AUTOSAR XML (schema 2.1.2)
standard types defined: Boolean
package /Komfortsystem
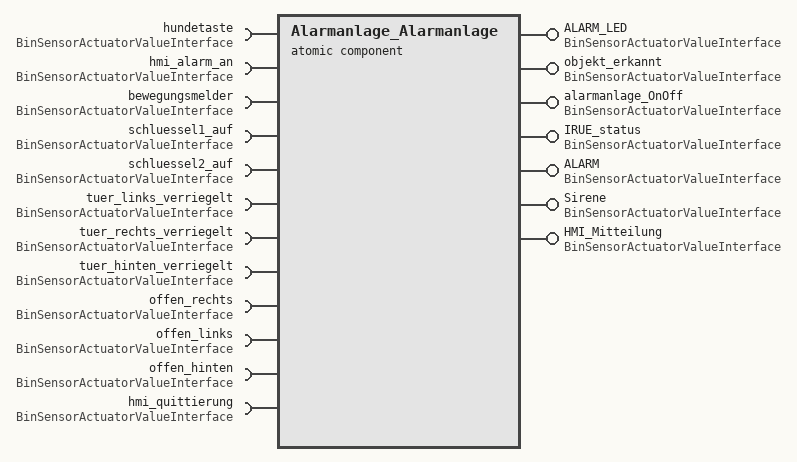
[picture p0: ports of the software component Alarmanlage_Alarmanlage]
  atomic software component type Alarmanlage_Alarmanlage  # @isComplex true
    11 x require port, all with required-interface=BinSensorActuatorValueInterface:
      hundetaste
      hmi_alarm_an
      bewegungsmelder
      schluessel1_auf
      schluessel2_auf
      tuer_links_verriegelt
      tuer_rechts_verriegelt
      tuer_hinten_verriegelt
      offen_rechts
      offen_links
      offen_hinten
    7 x provide port, all with provided-interface=BinSensorActuatorValueInterface:
      ALARM_LED
      objekt_erkannt
      alarmanlage_OnOff
      IRUE_status
      ALARM
      Sirene
      HMI_Mitteilung
    require port hmi_quittierung: required-interface=BinSensorActuatorValueInterface
  atomic software component type Alarmanlage_Bewegungsmelder  # __Sensor_Bewegungsmelder
    provide port status: provided-interface=BinSensorActuatorValueInterface
  atomic software component type Alarmanlage_Hundetaste  # __Sensor_Taster
    provide port taster_value: provided-interface=BinSensorActuatorValueInterface
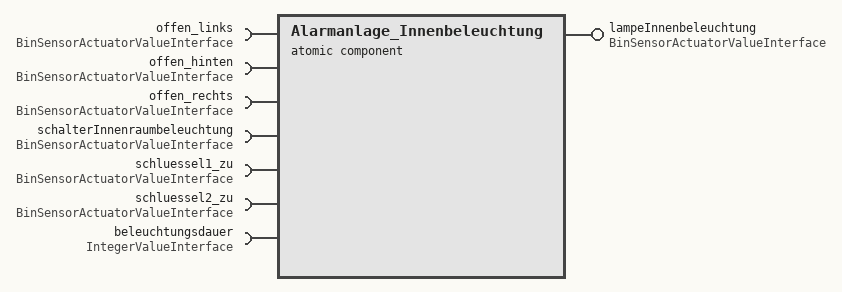
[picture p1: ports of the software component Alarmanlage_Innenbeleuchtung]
  atomic software component type Alarmanlage_Innenbeleuchtung  # @isComplex true
    7 x require port:
      offen_links: required-interface=BinSensorActuatorValueInterface
      offen_hinten: required-interface=BinSensorActuatorValueInterface
      offen_rechts: required-interface=BinSensorActuatorValueInterface
      schalterInnenraumbeleuchtung: required-interface=BinSensorActuatorValueInterface
      schluessel1_zu: required-interface=BinSensorActuatorValueInterface
      schluessel2_zu: required-interface=BinSensorActuatorValueInterface
      beleuchtungsdauer: required-interface=IntegerValueInterface
    provide port lampeInnenbeleuchtung: provided-interface=BinSensorActuatorValueInterface
  atomic software component type Alarmanlage_InnenbeleuchtungLampe  # __Actuator_LampeInnenbeleuchtung
    require port newStatus: required-interface=BinSensorActuatorValueInterface
  atomic software component type Alarmanlage_InnenraumBeleuchtungTaster  # __Sensor_Taster
    provide port taster_value: provided-interface=BinSensorActuatorValueInterface
  atomic software component type Alarmanlage_LED  # __Actuator_LED
    require port newStatus: required-interface=BinSensorActuatorValueInterface
  atomic software component type Alarmanlage_Sirene  # __Actuator_Sirene
    require port status: required-interface=BinSensorActuatorValueInterface
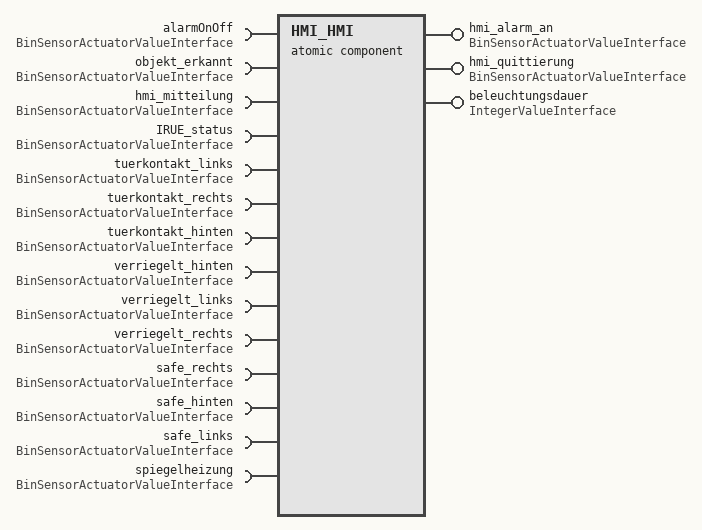
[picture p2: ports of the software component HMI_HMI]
  atomic software component type HMI_HMI  # @isComplex true
    13 x require port, all with required-interface=BinSensorActuatorValueInterface:
      alarmOnOff
      objekt_erkannt
      hmi_mitteilung
      IRUE_status
      tuerkontakt_links
      tuerkontakt_rechts
      tuerkontakt_hinten
      verriegelt_hinten
      verriegelt_links
      verriegelt_rechts
      safe_rechts
      safe_hinten
      safe_links
    provide port hmi_alarm_an: provided-interface=BinSensorActuatorValueInterface
    provide port hmi_quittierung: provided-interface=BinSensorActuatorValueInterface
    provide port beleuchtungsdauer: provided-interface=IntegerValueInterface
    require port spiegelheizung: required-interface=BinSensorActuatorValueInterface
  atomic software component type SensorAussentemperatur
    provide port unterEinGrad: provided-interface=BinSensorActuatorValueInterface
  atomic software component type SensorGeschwindigkeit
    provide port geschwindigkeit: provided-interface=IntegerValueInterface
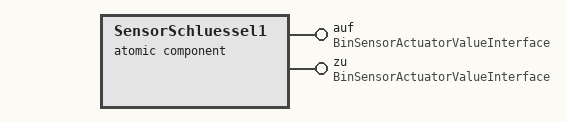
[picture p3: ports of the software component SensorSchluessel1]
  atomic software component type SensorSchluessel1
    provide port auf: provided-interface=BinSensorActuatorValueInterface
    provide port zu: provided-interface=BinSensorActuatorValueInterface
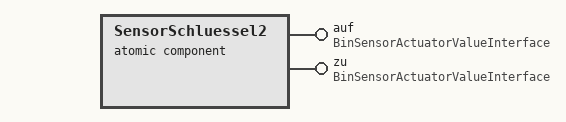
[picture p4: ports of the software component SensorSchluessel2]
  atomic software component type SensorSchluessel2
    provide port auf: provided-interface=BinSensorActuatorValueInterface
    provide port zu: provided-interface=BinSensorActuatorValueInterface
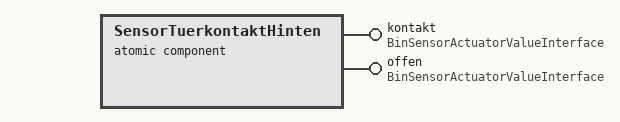
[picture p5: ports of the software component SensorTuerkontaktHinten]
  atomic software component type SensorTuerkontaktHinten
    provide port kontakt: provided-interface=BinSensorActuatorValueInterface
    provide port offen: provided-interface=BinSensorActuatorValueInterface
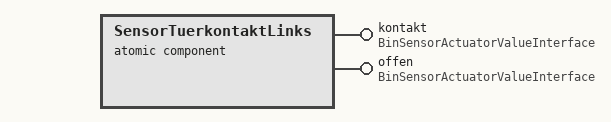
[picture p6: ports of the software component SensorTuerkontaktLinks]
  atomic software component type SensorTuerkontaktLinks
    provide port kontakt: provided-interface=BinSensorActuatorValueInterface
    provide port offen: provided-interface=BinSensorActuatorValueInterface
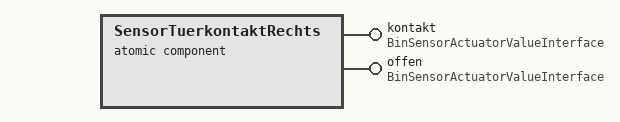
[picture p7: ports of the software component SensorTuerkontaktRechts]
  atomic software component type SensorTuerkontaktRechts
    provide port kontakt: provided-interface=BinSensorActuatorValueInterface
    provide port offen: provided-interface=BinSensorActuatorValueInterface
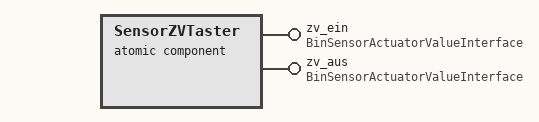
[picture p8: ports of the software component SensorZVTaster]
  atomic software component type SensorZVTaster
    provide port zv_ein: provided-interface=BinSensorActuatorValueInterface
    provide port zv_aus: provided-interface=BinSensorActuatorValueInterface
  atomic software component type TasterBlinker
    provide port taster_value: provided-interface=BinSensorActuatorValueInterface
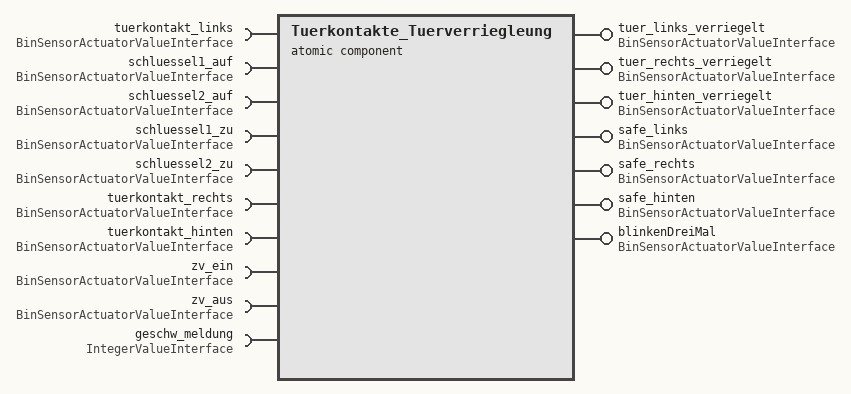
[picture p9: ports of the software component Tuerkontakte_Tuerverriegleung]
  atomic software component type Tuerkontakte_Tuerverriegleung  # @isComplex true
    10 x require port:
      tuerkontakt_links: required-interface=BinSensorActuatorValueInterface
      schluessel1_auf: required-interface=BinSensorActuatorValueInterface
      schluessel2_auf: required-interface=BinSensorActuatorValueInterface
      schluessel1_zu: required-interface=BinSensorActuatorValueInterface
      schluessel2_zu: required-interface=BinSensorActuatorValueInterface
      tuerkontakt_rechts: required-interface=BinSensorActuatorValueInterface
      tuerkontakt_hinten: required-interface=BinSensorActuatorValueInterface
      zv_ein: required-interface=BinSensorActuatorValueInterface
      zv_aus: required-interface=BinSensorActuatorValueInterface
      geschw_meldung: required-interface=IntegerValueInterface
    7 x provide port, all with provided-interface=BinSensorActuatorValueInterface:
      tuer_links_verriegelt
      tuer_rechts_verriegelt
      tuer_hinten_verriegelt
      safe_links
      safe_rechts
      safe_hinten
      blinkenDreiMal
  atomic software component type Tuersystem_Blinker
    require port blinker_status: required-interface=BinSensorActuatorValueInterface
  atomic software component type Tuersystem_Blinkerfunktionalitaet  # @isComplex true
    require port Blinker_CAN: required-interface=BinSensorActuatorValueInterface
    require port BlinkenDreiMal: required-interface=BinSensorActuatorValueInterface
    require port ALARM: required-interface=BinSensorActuatorValueInterface
    provide port blinker_status: provided-interface=BinSensorActuatorValueInterface
  atomic software component type Tuersystem_Fensterheber_BCD_A  # Actuator_LED
    require port newStatus: required-interface=BinSensorActuatorValueInterface
  atomic software component type Tuersystem_Fensterheber_BCD_B  # Actuator_LED
    require port newStatus: required-interface=BinSensorActuatorValueInterface
  atomic software component type Tuersystem_Fensterheber_BCD_C  # Actuator_LED
    require port newStatus: required-interface=BinSensorActuatorValueInterface
  atomic software component type Tuersystem_Fensterheber_BCD_D  # Actuator_LED
    require port newStatus: required-interface=BinSensorActuatorValueInterface
  atomic software component type Tuersystem_Fensterheber_Fensterbewegen  # @isComplex true
    4 x require port, all with required-interface=BinSensorActuatorValueInterface:
      fenster_hoch
      fenster_runter
      zv_ein
      init_abgeschlossen
    provide port fenster_hochfahren: provided-interface=BinSensorActuatorValueInterface
    provide port fenster_runterfahren: provided-interface=BinSensorActuatorValueInterface
  atomic software component type Tuersystem_Fensterheber_FensterheberMotor_Actuator
    require port moveDirection: required-interface=BinSensorActuatorValueInterface
    require port moveReverseDirection: required-interface=BinSensorActuatorValueInterface
  atomic software component type Tuersystem_Fensterheber_Fensterhoch_Taster  # Sensor_Taster
    provide port taster_value: provided-interface=BinSensorActuatorValueInterface
  atomic software component type Tuersystem_Fensterheber_Fensterpositionsbestimmung  # @isComplex true
    4 x require port, all with required-interface=BinSensorActuatorValueInterface:
      init_abgeschlossen
      impulsgeber
      fenster_faehrthoch
      fenster_faehrtrunter
    provide port AktImpulAnz: provided-interface=IntegerValueInterface
  atomic software component type Tuersystem_Fensterheber_Fensterrunter_Taster  # Sensor_Taster
    provide port taster_value: provided-interface=BinSensorActuatorValueInterface
  atomic software component type Tuersystem_Fensterheber_Impulsgeber
    provide port impuls: provided-interface=BinSensorActuatorValueInterface
  atomic software component type Tuersystem_Fensterheber_Initialisierung  # @isComplex true
    require port impulsgeber: required-interface=BinSensorActuatorValueInterface
    4 x provide port:
      init_abgeschlossen: provided-interface=BinSensorActuatorValueInterface
      fenster_hochfahren: provided-interface=BinSensorActuatorValueInterface
      fenster_runterfahren: provided-interface=BinSensorActuatorValueInterface
      impulseMax: provided-interface=IntegerValueInterface
  atomic software component type Tuersystem_Fensterheber_Klemmschutz  # @isComplex true
    5 x require port:
      fenster_hochfahren: required-interface=BinSensorActuatorValueInterface
      fenster_runterfahren: required-interface=BinSensorActuatorValueInterface
      impulsgeber: required-interface=BinSensorActuatorValueInterface
      AktImpulAnz: required-interface=IntegerValueInterface
      anschlag_oben_int: required-interface=IntegerValueInterface
    provide port fenster_hochfahren_act: provided-interface=BinSensorActuatorValueInterface
    provide port fenster_runterfahren_act: provided-interface=BinSensorActuatorValueInterface
  atomic software component type Tuersystem_Fensterheber_LEDAnzeige  # @isComplex true
    require port init_abschlossen: required-interface=BinSensorActuatorValueInterface
    require port AktImpulsAnz: required-interface=IntegerValueInterface
    require port impulsMax: required-interface=IntegerValueInterface
    5 x provide port:
      AnschlagObenInt: provided-interface=IntegerValueInterface
      BCD_A: provided-interface=BinSensorActuatorValueInterface
      BCD_B: provided-interface=BinSensorActuatorValueInterface
      BCD_D: provided-interface=BinSensorActuatorValueInterface
      BCD_C: provided-interface=BinSensorActuatorValueInterface
  atomic software component type Tuersystem_Spiegelheizung
    require port newValue: required-interface=BinSensorActuatorValueInterface
  atomic software component type Tuersystem_Spiegelstellung_LED_Horizontal_BCD_A  # Actuator_LED
    require port newStatus: required-interface=BinSensorActuatorValueInterface
    provide port LED_status: provided-interface=BinSensorActuatorValueInterface
  atomic software component type Tuersystem_Spiegelstellung_LED_Horizontal_BCD_B  # Actuator_LED
    require port newStatus: required-interface=BinSensorActuatorValueInterface
    provide port LED_status: provided-interface=BinSensorActuatorValueInterface
  atomic software component type Tuersystem_Spiegelstellung_LED_Horizontal_BCD_C  # Actuator_LED
    require port newStatus: required-interface=BinSensorActuatorValueInterface
    provide port LED_status: provided-interface=BinSensorActuatorValueInterface
  atomic software component type Tuersystem_Spiegelstellung_LED_Vertikal_BCD_A  # Actuator_LED
    require port newStatus: required-interface=BinSensorActuatorValueInterface
    provide port LED_status: provided-interface=BinSensorActuatorValueInterface
  atomic software component type Tuersystem_Spiegelstellung_LED_Vertikal_BCD_B  # Actuator_LED
    require port newStatus: required-interface=BinSensorActuatorValueInterface
    provide port LED_status: provided-interface=BinSensorActuatorValueInterface
  atomic software component type Tuersystem_Spiegelstellung_LED_Vertikal_BCD_C  # Actuator_LED
    require port newStatus: required-interface=BinSensorActuatorValueInterface
    provide port LED_status: provided-interface=BinSensorActuatorValueInterface
  atomic software component type Tuersystem_Spiegelstellung_SollHorzAnfahren  # @isComplex true
    4 x require port, all with required-interface=BinSensorActuatorValueInterface:
      schluessel1_auf
      Soll_Pos_Horz_BCD_A
      Soll_Pos_Horz_BCD_C
      Soll_Pos_Horz_BCD_B
    provide port spiegel_rechtsfahren: provided-interface=BinSensorActuatorValueInterface
    require port spiegel_links: required-interface=BinSensorActuatorValueInterface
    provide port spiegel_linksfahren: provided-interface=BinSensorActuatorValueInterface
    require port schluessel2_auf: required-interface=BinSensorActuatorValueInterface
    require port spiegel_rechts: required-interface=BinSensorActuatorValueInterface
    provide port LED_Horizontal_BCD_A: provided-interface=BinSensorActuatorValueInterface
    provide port LED_Horizontal_BCD_B: provided-interface=BinSensorActuatorValueInterface
    provide port LED_Horizontal_BCD_C: provided-interface=BinSensorActuatorValueInterface
  atomic software component type Tuersystem_Spiegelstellung_SollVertAnfahren  # @isComplex true
    4 x require port, all with required-interface=BinSensorActuatorValueInterface:
      spiegel_hoch
      spiegel_runter
      schluessel1_auf
      Soll_Pos_Vert_BCD_A
    provide port spiegel_hochfahren: provided-interface=BinSensorActuatorValueInterface
    require port Soll_Pos_Vert_BCD_B: required-interface=BinSensorActuatorValueInterface
    provide port spiegel_runterfahren: provided-interface=BinSensorActuatorValueInterface
    require port schluessel2_auf: required-interface=BinSensorActuatorValueInterface
    require port Soll_Pos_Vert_BCD_C: required-interface=BinSensorActuatorValueInterface
    provide port LED_Vertikal_BCD_A: provided-interface=BinSensorActuatorValueInterface
    provide port LED_Vertikal_BCD_B: provided-interface=BinSensorActuatorValueInterface
    provide port LED_Vertikal_BCD_C: provided-interface=BinSensorActuatorValueInterface
  atomic software component type Tuersystem_Spiegelstellung_SpiegelMotorHorizontal  # Actuator_SpiegelstellungMotor
    require port moveDirection: required-interface=BinSensorActuatorValueInterface
    require port moveReverseDirection: required-interface=BinSensorActuatorValueInterface
  atomic software component type Tuersystem_Spiegelstellung_SpiegelMotorVertikal  # Actuator_SpiegelstellungMotor
    require port moveDirection: required-interface=BinSensorActuatorValueInterface
    require port moveReverseDirection: required-interface=BinSensorActuatorValueInterface
  atomic software component type Tuersystem_Spiegelstellung_TasterSpiegelHoch  # TasterSpiegelHoch__Sensor_Taster
    provide port taster_value: provided-interface=BinSensorActuatorValueInterface
  atomic software component type Tuersystem_Spiegelstellung_TasterSpiegelLinks  # TasterSpiegelHoch__Sensor_Taster
    provide port taster_value: provided-interface=BinSensorActuatorValueInterface
  atomic software component type Tuersystem_Spiegelstellung_TasterSpiegelRechts  # TasterSpiegelHoch__Sensor_Taster
    provide port taster_value: provided-interface=BinSensorActuatorValueInterface
  atomic software component type Tuersystem_Spiegelstellung_TasterSpiegelRunter  # TasterSpiegelHoch__Sensor_Taster
    provide port taster_value: provided-interface=BinSensorActuatorValueInterface
  atomic software component type Tuersystem_Tueroeffner
    require port newStatus: required-interface=BinSensorActuatorValueInterface
  atomic software component type Tuersystem_TueroeffnerKoordinator
    4 x require port, all with required-interface=BinSensorActuatorValueInterface:
      taster_value
      schluessel1_auf
      schluessel2_auf
      zv_ein
    provide port newStatus: provided-interface=BinSensorActuatorValueInterface
  atomic software component type Tuersystem_TueroeffnerTaster
    provide port taster_value: provided-interface=BinSensorActuatorValueInterface
  7 x composition type:
    Alarmanlage
      13 x require port:
        hmi_alarm_an: required-interface=BinSensorActuatorValueInterface
        schluessel1_auf: required-interface=BinSensorActuatorValueInterface
        schluessel2_auf: required-interface=BinSensorActuatorValueInterface
        tuer_links_verriegelt: required-interface=BinSensorActuatorValueInterface
        tuer_rechts_verriegelt: required-interface=BinSensorActuatorValueInterface
        tuer_hinten_verriegelt: required-interface=BinSensorActuatorValueInterface
        offen_rechts: required-interface=BinSensorActuatorValueInterface
        offen_links: required-interface=BinSensorActuatorValueInterface
        offen_hinten: required-interface=BinSensorActuatorValueInterface
        hmi_quittierung: required-interface=BinSensorActuatorValueInterface
        schluessel1_zu: required-interface=BinSensorActuatorValueInterface
        schluessel2_zu: required-interface=BinSensorActuatorValueInterface
        beleuchtungsdauer: required-interface=IntegerValueInterface
      5 x provide port, all with provided-interface=BinSensorActuatorValueInterface:
        HMI_Mitteilung
        ALARM
        IRUE_status
        alarmanlage_OnOff
        objekt_erkannt
      8 x component:
        Alarmanlage_Alarmanlage: type=Alarmanlage_Alarmanlage  # @group 2
        Alarmanlage_Bewegungsmelder: type=Alarmanlage_Bewegungsmelder  # @group 2
        Alarmanlage_Hundetaste: type=Alarmanlage_Hundetaste  # @group 2
        Alarmanlage_Innenbeleuchtung: type=Alarmanlage_Innenbeleuchtung  # @group 2
        Alarmanlage_LED: type=Alarmanlage_LED  # @group 2
        Alarmanlage_Sirene: type=Alarmanlage_Sirene  # @group 2
        Alarmanlage_InnenbeleuchtungLampe: type=Alarmanlage_InnenbeleuchtungLampe  # @group 2
        Alarmanlage_InnenraumBeleuchtungTaster: type=Alarmanlage_InnenraumBeleuchtungTaster  # @group 2
      delegate Alarmanlage_Innenbeleuchtung.schluessel1_zu <-> outer port Alarmanlage/schluessel1_zu
      delegate Alarmanlage_Innenbeleuchtung.schluessel2_zu <-> outer port Alarmanlage/schluessel2_zu
      delegate Alarmanlage_Innenbeleuchtung.offen_links <-> outer port Alarmanlage/offen_links
      delegate Alarmanlage_Innenbeleuchtung.offen_hinten <-> outer port Alarmanlage/offen_hinten
      delegate Alarmanlage_Innenbeleuchtung.offen_rechts <-> outer port Alarmanlage/offen_rechts
      delegate Alarmanlage_Alarmanlage.objekt_erkannt <-> outer port Alarmanlage/objekt_erkannt
      delegate Alarmanlage_Alarmanlage.alarmanlage_OnOff <-> outer port Alarmanlage/alarmanlage_OnOff
      delegate Alarmanlage_Alarmanlage.ALARM <-> outer port Alarmanlage/ALARM
      delegate Alarmanlage_Alarmanlage.IRUE_status <-> outer port Alarmanlage/IRUE_status
      delegate Alarmanlage_Alarmanlage.HMI_Mitteilung <-> outer port Alarmanlage/HMI_Mitteilung
      delegate Alarmanlage_Alarmanlage.hmi_quittierung <-> outer port Alarmanlage/hmi_quittierung
      delegate Alarmanlage_Alarmanlage.tuer_hinten_verriegelt <-> outer port Alarmanlage/tuer_hinten_verriegelt
      delegate Alarmanlage_Alarmanlage.tuer_rechts_verriegelt <-> outer port Alarmanlage/tuer_rechts_verriegelt
      delegate Alarmanlage_Alarmanlage.tuer_links_verriegelt <-> outer port Alarmanlage/tuer_links_verriegelt
      delegate Alarmanlage_Alarmanlage.schluessel2_auf <-> outer port Alarmanlage/schluessel2_auf
      delegate Alarmanlage_Alarmanlage.schluessel1_auf <-> outer port Alarmanlage/schluessel1_auf
      delegate Alarmanlage_Alarmanlage.hmi_alarm_an <-> outer port Alarmanlage/hmi_alarm_an
      delegate Alarmanlage_Alarmanlage.offen_rechts <-> outer port Alarmanlage/offen_rechts
      delegate Alarmanlage_Alarmanlage.offen_hinten <-> outer port Alarmanlage/offen_hinten
      delegate Alarmanlage_Alarmanlage.offen_links <-> outer port Alarmanlage/offen_links
      delegate Alarmanlage_Innenbeleuchtung.beleuchtungsdauer <-> outer port Alarmanlage/beleuchtungsdauer
      connect Alarmanlage_Innenbeleuchtung.lampeInnenbeleuchtung -> Alarmanlage_InnenbeleuchtungLampe.newStatus
      connect Alarmanlage_Alarmanlage.ALARM_LED -> Alarmanlage_LED.newStatus
      connect Alarmanlage_Alarmanlage.Sirene -> Alarmanlage_Sirene.status
      connect Alarmanlage_Bewegungsmelder.status -> Alarmanlage_Alarmanlage.bewegungsmelder
      connect Alarmanlage_Hundetaste.taster_value -> Alarmanlage_Alarmanlage.hundetaste
      connect Alarmanlage_InnenraumBeleuchtungTaster.taster_value -> Alarmanlage_Innenbeleuchtung.schalterInnenraumbeleuchtung
    Human Machine Interface
      13 x require port, all with required-interface=BinSensorActuatorValueInterface:
        alarmOnOff
        objekt_erkannt
        hmi_mitteilung
        IRUE_status
        tuerkontakt_links
        tuerkontakt_rechts
        tuerkontakt_hinten
        verriegelt_hinten
        verriegelt_links
        verriegelt_rechts
        safe_rechts
        safe_hinten
        safe_links
      provide port hmi_alarm_an: provided-interface=BinSensorActuatorValueInterface
      provide port hmi_quittierung: provided-interface=BinSensorActuatorValueInterface
      provide port beleuchtungsdauer: provided-interface=IntegerValueInterface
      require port spiegelheizung: required-interface=BinSensorActuatorValueInterface
      component HMI_HMI: type=HMI_HMI  # @group 3
      delegate HMI_HMI.alarmOnOff <-> outer port Human Machine Interface/alarmOnOff
      delegate HMI_HMI.objekt_erkannt <-> outer port Human Machine Interface/objekt_erkannt
      delegate HMI_HMI.hmi_mitteilung <-> outer port Human Machine Interface/hmi_mitteilung
      delegate HMI_HMI.IRUE_status <-> outer port Human Machine Interface/IRUE_status
      delegate HMI_HMI.tuerkontakt_links <-> outer port Human Machine Interface/tuerkontakt_links
      delegate HMI_HMI.tuerkontakt_rechts <-> outer port Human Machine Interface/tuerkontakt_rechts
      delegate HMI_HMI.tuerkontakt_hinten <-> outer port Human Machine Interface/tuerkontakt_hinten
      delegate HMI_HMI.verriegelt_hinten <-> outer port Human Machine Interface/verriegelt_hinten
      delegate HMI_HMI.verriegelt_links <-> outer port Human Machine Interface/verriegelt_links
      delegate HMI_HMI.verriegelt_rechts <-> outer port Human Machine Interface/verriegelt_rechts
      delegate HMI_HMI.safe_rechts <-> outer port Human Machine Interface/safe_rechts
      delegate HMI_HMI.safe_hinten <-> outer port Human Machine Interface/safe_hinten
      delegate HMI_HMI.safe_links <-> outer port Human Machine Interface/safe_links
      delegate HMI_HMI.hmi_alarm_an <-> outer port Human Machine Interface/hmi_alarm_an
      delegate HMI_HMI.hmi_quittierung <-> outer port Human Machine Interface/hmi_quittierung
      delegate HMI_HMI.beleuchtungsdauer <-> outer port Human Machine Interface/beleuchtungsdauer
      delegate HMI_HMI.spiegelheizung <-> outer port Human Machine Interface/spiegelheizung
    SWA_Komfortsystem
      13 x component:
        Alarmanlage: type=Alarmanlage  # @group 2
        Tuerkontakte: type=Tuerkontakte  # @group 1
        Tuersystem: type=Tuersystem  # @group 0
        Human Machine Interface: type=Human Machine Interface  # @group 3
        SensorAussentemperatur: type=SensorAussentemperatur  # @group 4
        SensorGeschwindigkeit: type=SensorGeschwindigkeit  # @group 4
        SensorZVTaster: type=SensorZVTaster  # @group 2
        SensorTuerkontaktHinten: type=SensorTuerkontaktHinten  # @group 1
        SensorTuerkontaktLinks: type=SensorTuerkontaktLinks  # @group 1
        SensorTuerkontaktRechts: type=SensorTuerkontaktRechts  # @group 1
        SensorSchluessel1: type=SensorSchluessel1  # @group 1
        SensorSchluessel2: type=SensorSchluessel2  # @group 1
        TasterBlinker: type=TasterBlinker  # @group 4
      connect Alarmanlage.ALARM -> Tuersystem.ALARM
      connect Tuerkontakte.blinkenDreiMal -> Tuersystem.BlinkenDreiMal
      connect SensorGeschwindigkeit.geschwindigkeit -> Tuerkontakte.geschw_meldung
      connect SensorZVTaster.zv_ein -> Tuerkontakte.zv_ein
      connect SensorZVTaster.zv_aus -> Tuerkontakte.zv_aus
      connect Tuerkontakte.tuer_links_verriegelt -> Alarmanlage.tuer_links_verriegelt
      connect Tuerkontakte.tuer_rechts_verriegelt -> Alarmanlage.tuer_rechts_verriegelt
      connect Tuerkontakte.tuer_hinten_verriegelt -> Alarmanlage.tuer_hinten_verriegelt
      connect SensorAussentemperatur.unterEinGrad -> Tuersystem.spiegelheizung
      connect SensorTuerkontaktHinten.kontakt -> Tuerkontakte.tuerkontakt_hinten
      connect SensorTuerkontaktHinten.offen -> Alarmanlage.offen_hinten
      connect SensorTuerkontaktRechts.offen -> Alarmanlage.offen_rechts
      connect SensorTuerkontaktRechts.kontakt -> Tuerkontakte.tuerkontakt_rechts
      connect SensorTuerkontaktLinks.offen -> Alarmanlage.offen_links
      connect SensorTuerkontaktLinks.kontakt -> Tuerkontakte.tuerkontakt_links
      connect SensorSchluessel1.auf -> Alarmanlage.schluessel1_auf
      connect SensorSchluessel1.zu -> Alarmanlage.schluessel1_zu
      connect SensorSchluessel2.auf -> Alarmanlage.schluessel2_auf
      connect SensorSchluessel2.zu -> Alarmanlage.schluessel2_zu
      connect SensorSchluessel1.auf -> Tuerkontakte.schluessel1_auf
      connect SensorSchluessel1.zu -> Tuerkontakte.schluessel1_zu
      connect SensorSchluessel2.auf -> Tuerkontakte.schluessel2_auf
      connect SensorSchluessel2.zu -> Tuerkontakte.schluessel2_zu
      connect SensorSchluessel1.auf -> Tuersystem.schluessel1_auf
      connect SensorSchluessel2.auf -> Tuersystem.schluessel2_auf
      connect TasterBlinker.taster_value -> Tuersystem.Blinker_CAN
      connect SensorZVTaster.zv_ein -> Tuersystem.zv_ein
      connect Tuerkontakte.safe_hinten -> Human Machine Interface.safe_hinten
      connect Tuerkontakte.safe_links -> Human Machine Interface.safe_links
      connect Tuerkontakte.safe_rechts -> Human Machine Interface.safe_rechts
      connect Alarmanlage.objekt_erkannt -> Human Machine Interface.objekt_erkannt
      connect Alarmanlage.alarmanlage_OnOff -> Human Machine Interface.alarmOnOff
      connect Alarmanlage.HMI_Mitteilung -> Human Machine Interface.hmi_mitteilung
      connect Alarmanlage.IRUE_status -> Human Machine Interface.IRUE_status
      connect SensorTuerkontaktLinks.kontakt -> Human Machine Interface.tuerkontakt_links
      connect SensorTuerkontaktRechts.kontakt -> Human Machine Interface.tuerkontakt_rechts
      connect SensorTuerkontaktHinten.kontakt -> Human Machine Interface.tuerkontakt_hinten
      connect Human Machine Interface.hmi_quittierung -> Alarmanlage.hmi_quittierung
      connect Human Machine Interface.beleuchtungsdauer -> Alarmanlage.beleuchtungsdauer
      connect Human Machine Interface.hmi_alarm_an -> Alarmanlage.hmi_alarm_an
      connect Tuerkontakte.tuer_hinten_verriegelt -> Human Machine Interface.verriegelt_hinten
      connect Tuerkontakte.tuer_links_verriegelt -> Human Machine Interface.verriegelt_links
      connect Tuerkontakte.tuer_rechts_verriegelt -> Human Machine Interface.verriegelt_rechts
      connect SensorAussentemperatur.unterEinGrad -> Human Machine Interface.spiegelheizung
    Tuerkontakte
      10 x require port:
        tuerkontakt_links: required-interface=BinSensorActuatorValueInterface
        schluessel1_zu: required-interface=BinSensorActuatorValueInterface
        schluessel2_auf: required-interface=BinSensorActuatorValueInterface
        schluessel2_zu: required-interface=BinSensorActuatorValueInterface
        schluessel1_auf: required-interface=BinSensorActuatorValueInterface
        tuerkontakt_rechts: required-interface=BinSensorActuatorValueInterface
        tuerkontakt_hinten: required-interface=BinSensorActuatorValueInterface
        zv_ein: required-interface=BinSensorActuatorValueInterface
        zv_aus: required-interface=BinSensorActuatorValueInterface
        geschw_meldung: required-interface=IntegerValueInterface
      7 x provide port, all with provided-interface=BinSensorActuatorValueInterface:
        tuer_links_verriegelt
        tuer_rechts_verriegelt
        tuer_hinten_verriegelt
        blinkenDreiMal
        safe_links
        safe_rechts
        safe_hinten
      component Tuerkontakte_Tuerverriegleung: type=Tuerkontakte_Tuerverriegleung  # @group 1
      delegate Tuerkontakte_Tuerverriegleung.tuer_links_verriegelt <-> outer port Tuerkontakte/tuer_links_verriegelt
      delegate Tuerkontakte_Tuerverriegleung.tuer_rechts_verriegelt <-> outer port Tuerkontakte/tuer_rechts_verriegelt
      delegate Tuerkontakte_Tuerverriegleung.tuer_hinten_verriegelt <-> outer port Tuerkontakte/tuer_hinten_verriegelt
      delegate Tuerkontakte_Tuerverriegleung.safe_links <-> outer port Tuerkontakte/safe_links
      delegate Tuerkontakte_Tuerverriegleung.safe_rechts <-> outer port Tuerkontakte/safe_rechts
      delegate Tuerkontakte_Tuerverriegleung.safe_hinten <-> outer port Tuerkontakte/safe_hinten
      delegate Tuerkontakte_Tuerverriegleung.blinkenDreiMal <-> outer port Tuerkontakte/blinkenDreiMal
      delegate Tuerkontakte_Tuerverriegleung.tuerkontakt_links <-> outer port Tuerkontakte/tuerkontakt_links
      delegate Tuerkontakte_Tuerverriegleung.schluessel2_auf <-> outer port Tuerkontakte/schluessel2_auf
      delegate Tuerkontakte_Tuerverriegleung.schluessel2_zu <-> outer port Tuerkontakte/schluessel2_zu
      delegate Tuerkontakte_Tuerverriegleung.schluessel1_zu <-> outer port Tuerkontakte/schluessel1_zu
      delegate Tuerkontakte_Tuerverriegleung.schluessel1_auf <-> outer port Tuerkontakte/schluessel1_auf
      delegate Tuerkontakte_Tuerverriegleung.tuerkontakt_rechts <-> outer port Tuerkontakte/tuerkontakt_rechts
      delegate Tuerkontakte_Tuerverriegleung.tuerkontakt_hinten <-> outer port Tuerkontakte/tuerkontakt_hinten
      delegate Tuerkontakte_Tuerverriegleung.zv_ein <-> outer port Tuerkontakte/zv_ein
      delegate Tuerkontakte_Tuerverriegleung.zv_aus <-> outer port Tuerkontakte/zv_aus
      delegate Tuerkontakte_Tuerverriegleung.geschw_meldung <-> outer port Tuerkontakte/geschw_meldung
    Tuersystem
      7 x require port, all with required-interface=BinSensorActuatorValueInterface:
        schluessel1_auf
        schluessel2_auf
        zv_ein
        ALARM
        BlinkenDreiMal
        Blinker_CAN
        spiegelheizung
      8 x component:
        Tuersystem_Fensterheber: type=Tuersystem_Fensterheber
        Tuersystem_Spiegelstellung: type=Tuersystem_Spiegelstellung
        Tuersystem_Blinker: type=Tuersystem_Blinker  # @group 0
        Tuersystem_Blinkerfunktionalitaet: type=Tuersystem_Blinkerfunktionalitaet  # @group 0
        Tuersystem_Spiegelheizung: type=Tuersystem_Spiegelheizung  # @group 0
        Tuersystem_Tueroeffner: type=Tuersystem_Tueroeffner  # @group 0
        Tuersystem_TueroeffnerTaster: type=Tuersystem_TueroeffnerTaster  # @group 0
        Tuersystem_TueroeffnerKoordinator: type=Tuersystem_TueroeffnerKoordinator
      delegate Tuersystem_Spiegelstellung.schluessel1_auf <-> outer port Tuersystem/schluessel1_auf
      delegate Tuersystem_Spiegelstellung.schluessel2_auf <-> outer port Tuersystem/schluessel2_auf
      delegate Tuersystem_Fensterheber.zv_ein <-> outer port Tuersystem/zv_ein
      delegate Tuersystem_Blinkerfunktionalitaet.BlinkenDreiMal <-> outer port Tuersystem/BlinkenDreiMal
      delegate Tuersystem_Spiegelheizung.newValue <-> outer port Tuersystem/spiegelheizung
      delegate Tuersystem_Blinkerfunktionalitaet.Blinker_CAN <-> outer port Tuersystem/Blinker_CAN
      delegate Tuersystem_Blinkerfunktionalitaet.ALARM <-> outer port Tuersystem/ALARM
      delegate Tuersystem_TueroeffnerKoordinator.schluessel1_auf <-> outer port Tuersystem/schluessel1_auf
      delegate Tuersystem_TueroeffnerKoordinator.schluessel2_auf <-> outer port Tuersystem/schluessel2_auf
      delegate Tuersystem_TueroeffnerKoordinator.zv_ein <-> outer port Tuersystem/zv_ein
      connect Tuersystem_Blinkerfunktionalitaet.blinker_status -> Tuersystem_Blinker.blinker_status
      connect Tuersystem_TueroeffnerTaster.taster_value -> Tuersystem_TueroeffnerKoordinator.taster_value
      connect Tuersystem_TueroeffnerKoordinator.newStatus -> Tuersystem_Tueroeffner.newStatus
    Tuersystem_Fensterheber
      require port zv_ein: required-interface=BinSensorActuatorValueInterface
      13 x component:
        Tuersystem_Fensterheber_Fensterbewegen: type=Tuersystem_Fensterheber_Fensterbewegen  # @group 0
        Tuersystem_Fensterheber_Fensterpositionsbestimmung: type=Tuersystem_Fensterheber_Fensterpositionsbestimmung  # @group 0
        Tuersystem_Fensterheber_Impulsgeber: type=Tuersystem_Fensterheber_Impulsgeber  # @group 0
        Tuersystem_Fensterheber_Initialisierung: type=Tuersystem_Fensterheber_Initialisierung  # @group 0
        Tuersystem_Fensterheber_Klemmschutz: type=Tuersystem_Fensterheber_Klemmschutz  # @group 0
        Tuersystem_Fensterheber_LEDAnzeige: type=Tuersystem_Fensterheber_LEDAnzeige  # @group 0
        Tuersystem_Fensterheber_FensterheberMotor_Actuator: type=Tuersystem_Fensterheber_FensterheberMotor_Actuator  # @group 0
        Tuersystem_Fensterheber_BCD_A: type=Tuersystem_Fensterheber_BCD_A  # @group 0
        Tuersystem_Fensterheber_BCD_B: type=Tuersystem_Fensterheber_BCD_B  # @group 0
        Tuersystem_Fensterheber_BCD_C: type=Tuersystem_Fensterheber_BCD_C  # @group 0
        Tuersystem_Fensterheber_BCD_D: type=Tuersystem_Fensterheber_BCD_D  # @group 0
        Tuersystem_Fensterheber_Fensterhoch_Taster: type=Tuersystem_Fensterheber_Fensterhoch_Taster  # @group 0
        Tuersystem_Fensterheber_Fensterrunter_Taster: type=Tuersystem_Fensterheber_Fensterrunter_Taster  # @group 0
      delegate Tuersystem_Fensterheber_Fensterbewegen.zv_ein <-> outer port Tuersystem_Fensterheber/zv_ein
      connect Tuersystem_Fensterheber_Fensterbewegen.fenster_hochfahren -> Tuersystem_Fensterheber_Klemmschutz.fenster_hochfahren
      connect Tuersystem_Fensterheber_Fensterbewegen.fenster_runterfahren -> Tuersystem_Fensterheber_Klemmschutz.fenster_runterfahren
      connect Tuersystem_Fensterheber_Impulsgeber.impuls -> Tuersystem_Fensterheber_Klemmschutz.impulsgeber
      connect Tuersystem_Fensterheber_Klemmschutz.fenster_hochfahren_act -> Tuersystem_Fensterheber_FensterheberMotor_Actuator.moveDirection
      connect Tuersystem_Fensterheber_Klemmschutz.fenster_runterfahren_act -> Tuersystem_Fensterheber_FensterheberMotor_Actuator.moveReverseDirection
      connect Tuersystem_Fensterheber_LEDAnzeige.AnschlagObenInt -> Tuersystem_Fensterheber_Klemmschutz.anschlag_oben_int
      connect Tuersystem_Fensterheber_Initialisierung.init_abgeschlossen -> Tuersystem_Fensterheber_LEDAnzeige.init_abschlossen
      connect Tuersystem_Fensterheber_Fensterpositionsbestimmung.AktImpulAnz -> Tuersystem_Fensterheber_LEDAnzeige.AktImpulsAnz
      connect Tuersystem_Fensterheber_Initialisierung.impulseMax -> Tuersystem_Fensterheber_LEDAnzeige.impulsMax
      connect Tuersystem_Fensterheber_Initialisierung.fenster_hochfahren -> Tuersystem_Fensterheber_FensterheberMotor_Actuator.moveDirection
      connect Tuersystem_Fensterheber_Initialisierung.fenster_runterfahren -> Tuersystem_Fensterheber_FensterheberMotor_Actuator.moveReverseDirection
      connect Tuersystem_Fensterheber_Initialisierung.init_abgeschlossen -> Tuersystem_Fensterheber_Fensterpositionsbestimmung.init_abgeschlossen
      connect Tuersystem_Fensterheber_Impulsgeber.impuls -> Tuersystem_Fensterheber_Fensterpositionsbestimmung.impulsgeber
      connect Tuersystem_Fensterheber_Klemmschutz.fenster_hochfahren_act -> Tuersystem_Fensterheber_Fensterpositionsbestimmung.fenster_faehrthoch
      connect Tuersystem_Fensterheber_Klemmschutz.fenster_runterfahren_act -> Tuersystem_Fensterheber_Fensterpositionsbestimmung.fenster_faehrtrunter
      connect Tuersystem_Fensterheber_Fensterpositionsbestimmung.AktImpulAnz -> Tuersystem_Fensterheber_Klemmschutz.AktImpulAnz
      connect Tuersystem_Fensterheber_Impulsgeber.impuls -> Tuersystem_Fensterheber_Initialisierung.impulsgeber
      connect Tuersystem_Fensterheber_Initialisierung.init_abgeschlossen -> Tuersystem_Fensterheber_Fensterbewegen.init_abgeschlossen
      connect Tuersystem_Fensterheber_LEDAnzeige.BCD_A -> Tuersystem_Fensterheber_BCD_A.newStatus
      connect Tuersystem_Fensterheber_LEDAnzeige.BCD_B -> Tuersystem_Fensterheber_BCD_B.newStatus
      connect Tuersystem_Fensterheber_LEDAnzeige.BCD_C -> Tuersystem_Fensterheber_BCD_C.newStatus
      connect Tuersystem_Fensterheber_LEDAnzeige.BCD_D -> Tuersystem_Fensterheber_BCD_D.newStatus
      connect Tuersystem_Fensterheber_Fensterrunter_Taster.taster_value -> Tuersystem_Fensterheber_Fensterbewegen.fenster_runter
      connect Tuersystem_Fensterheber_Fensterhoch_Taster.taster_value -> Tuersystem_Fensterheber_Fensterbewegen.fenster_hoch
    Tuersystem_Spiegelstellung
      require port schluessel1_auf: required-interface=BinSensorActuatorValueInterface
      require port schluessel2_auf: required-interface=BinSensorActuatorValueInterface
      14 x component:
        Tuersystem_Spiegelstellung_SollHorzAnfahren: type=Tuersystem_Spiegelstellung_SollHorzAnfahren  # @group 0
        Tuersystem_Spiegelstellung_SollVertAnfahren: type=Tuersystem_Spiegelstellung_SollVertAnfahren  # @group 0
        Tuersystem_Spiegelstellung_LED_Vertikal_BCD_A: type=Tuersystem_Spiegelstellung_LED_Vertikal_BCD_A  # @group 0
        Tuersystem_Spiegelstellung_LED_Vertikal_BCD_B: type=Tuersystem_Spiegelstellung_LED_Vertikal_BCD_B  # @group 0
        Tuersystem_Spiegelstellung_LED_Vertikal_BCD_C: type=Tuersystem_Spiegelstellung_LED_Vertikal_BCD_C  # @group 0
        Tuersystem_Spiegelstellung_LED_Horizontal_BCD_A: type=Tuersystem_Spiegelstellung_LED_Horizontal_BCD_A  # @group 0
        Tuersystem_Spiegelstellung_LED_Horizontal_BCD_B: type=Tuersystem_Spiegelstellung_LED_Horizontal_BCD_B  # @group 0
        Tuersystem_Spiegelstellung_LED_Horizontal_BCD_C: type=Tuersystem_Spiegelstellung_LED_Horizontal_BCD_C  # @group 0
        Tuersystem_Spiegelstellung_SpiegelMotorHorizontal: type=Tuersystem_Spiegelstellung_SpiegelMotorHorizontal  # @group 0
        Tuersystem_Spiegelstellung_SpiegelMotorVertikal: type=Tuersystem_Spiegelstellung_SpiegelMotorVertikal  # @group 0
        Tuersystem_Spiegelstellung_TasterSpiegelHoch: type=Tuersystem_Spiegelstellung_TasterSpiegelHoch  # @group 0
        Tuersystem_Spiegelstellung_TasterSpiegelRunter: type=Tuersystem_Spiegelstellung_TasterSpiegelRunter  # @group 0
        Tuersystem_Spiegelstellung_TasterSpiegelLinks: type=Tuersystem_Spiegelstellung_TasterSpiegelLinks  # @group 0
        Tuersystem_Spiegelstellung_TasterSpiegelRechts: type=Tuersystem_Spiegelstellung_TasterSpiegelRechts  # @group 0
      delegate Tuersystem_Spiegelstellung_SollVertAnfahren.schluessel1_auf <-> outer port Tuersystem_Spiegelstellung/schluessel1_auf
      delegate Tuersystem_Spiegelstellung_SollVertAnfahren.schluessel2_auf <-> outer port Tuersystem_Spiegelstellung/schluessel2_auf
      delegate Tuersystem_Spiegelstellung_SollHorzAnfahren.schluessel2_auf <-> outer port Tuersystem_Spiegelstellung/schluessel2_auf
      delegate Tuersystem_Spiegelstellung_SollHorzAnfahren.schluessel1_auf <-> outer port Tuersystem_Spiegelstellung/schluessel1_auf
      connect Tuersystem_Spiegelstellung_TasterSpiegelHoch.taster_value -> Tuersystem_Spiegelstellung_SollVertAnfahren.spiegel_hoch
      connect Tuersystem_Spiegelstellung_TasterSpiegelRunter.taster_value -> Tuersystem_Spiegelstellung_SollVertAnfahren.spiegel_runter
      connect Tuersystem_Spiegelstellung_TasterSpiegelRechts.taster_value -> Tuersystem_Spiegelstellung_SollHorzAnfahren.spiegel_rechts
      connect Tuersystem_Spiegelstellung_TasterSpiegelLinks.taster_value -> Tuersystem_Spiegelstellung_SollHorzAnfahren.spiegel_links
      connect Tuersystem_Spiegelstellung_SollVertAnfahren.spiegel_hochfahren -> Tuersystem_Spiegelstellung_SpiegelMotorVertikal.moveDirection
      connect Tuersystem_Spiegelstellung_SollVertAnfahren.spiegel_runterfahren -> Tuersystem_Spiegelstellung_SpiegelMotorVertikal.moveReverseDirection
      connect Tuersystem_Spiegelstellung_SollHorzAnfahren.spiegel_rechtsfahren -> Tuersystem_Spiegelstellung_SpiegelMotorHorizontal.moveDirection
      connect Tuersystem_Spiegelstellung_SollHorzAnfahren.spiegel_linksfahren -> Tuersystem_Spiegelstellung_SpiegelMotorHorizontal.moveReverseDirection
      connect Tuersystem_Spiegelstellung_LED_Vertikal_BCD_A.LED_status -> Tuersystem_Spiegelstellung_SollVertAnfahren.Soll_Pos_Vert_BCD_A
      connect Tuersystem_Spiegelstellung_LED_Vertikal_BCD_B.LED_status -> Tuersystem_Spiegelstellung_SollVertAnfahren.Soll_Pos_Vert_BCD_B
      connect Tuersystem_Spiegelstellung_LED_Vertikal_BCD_C.LED_status -> Tuersystem_Spiegelstellung_SollVertAnfahren.Soll_Pos_Vert_BCD_C
      connect Tuersystem_Spiegelstellung_LED_Horizontal_BCD_A.LED_status -> Tuersystem_Spiegelstellung_SollHorzAnfahren.Soll_Pos_Horz_BCD_A
      connect Tuersystem_Spiegelstellung_LED_Horizontal_BCD_B.LED_status -> Tuersystem_Spiegelstellung_SollHorzAnfahren.Soll_Pos_Horz_BCD_C
      connect Tuersystem_Spiegelstellung_LED_Horizontal_BCD_C.LED_status -> Tuersystem_Spiegelstellung_SollHorzAnfahren.Soll_Pos_Horz_BCD_B
      connect Tuersystem_Spiegelstellung_SollVertAnfahren.LED_Vertikal_BCD_A -> Tuersystem_Spiegelstellung_LED_Vertikal_BCD_A.newStatus
      connect Tuersystem_Spiegelstellung_SollVertAnfahren.LED_Vertikal_BCD_B -> Tuersystem_Spiegelstellung_LED_Vertikal_BCD_B.newStatus
      connect Tuersystem_Spiegelstellung_SollVertAnfahren.LED_Vertikal_BCD_C -> Tuersystem_Spiegelstellung_LED_Vertikal_BCD_C.newStatus
      connect Tuersystem_Spiegelstellung_SollHorzAnfahren.LED_Horizontal_BCD_A -> Tuersystem_Spiegelstellung_LED_Horizontal_BCD_A.newStatus
      connect Tuersystem_Spiegelstellung_SollHorzAnfahren.LED_Horizontal_BCD_B -> Tuersystem_Spiegelstellung_LED_Horizontal_BCD_B.newStatus
      connect Tuersystem_Spiegelstellung_SollHorzAnfahren.LED_Horizontal_BCD_C -> Tuersystem_Spiegelstellung_LED_Horizontal_BCD_C.newStatus
  51 x implementation, all with behavior=Komfortsystem/InternalBehavior, programming-language=C:
    Implementation
      resource consumption Implementation
    Implementation
      resource consumption Implementation
    Implementation
      resource consumption Implementation
    Implementation
      resource consumption Implementation
    Implementation
      resource consumption Implementation
    Implementation
      resource consumption Implementation
    Implementation
      resource consumption Implementation
    Implementation
      resource consumption Implementation
    Implementation
      resource consumption Implementation
    Implementation
      resource consumption Implementation
    Implementation
      resource consumption Implementation
    Implementation
      resource consumption Implementation
    Implementation
      resource consumption Implementation
    Implementation
      resource consumption Implementation
    Implementation
      resource consumption Implementation
    Implementation
      resource consumption Implementation
    Implementation
      resource consumption Implementation
    Implementation
      resource consumption Implementation
    Implementation
      resource consumption Implementation
    Implementation
      resource consumption Implementation
    Implementation
      resource consumption Implementation
    Implementation
      resource consumption Implementation
    Implementation
      resource consumption Implementation
    Implementation
      resource consumption Implementation
    Implementation
      resource consumption Implementation
    Implementation
      resource consumption Implementation
    Implementation
      resource consumption Implementation
    Implementation
      resource consumption Implementation
    Implementation
      resource consumption Implementation
    Implementation
      resource consumption Implementation
    Implementation
      resource consumption Implementation
    Implementation
      resource consumption Implementation
    Implementation
      resource consumption Implementation
    Implementation
      resource consumption Implementation
    Implementation
      resource consumption Implementation
    Implementation
      resource consumption Implementation
    Implementation
      resource consumption Implementation
    Implementation
      resource consumption Implementation
    Implementation
      resource consumption Implementation
    Implementation
      resource consumption Implementation
    Implementation
      resource consumption Implementation
    Implementation
      resource consumption Implementation
    Implementation
      resource consumption Implementation
    Implementation
      resource consumption Implementation
    Implementation
      resource consumption Implementation
    Implementation
      resource consumption Implementation
    Implementation
      resource consumption Implementation
    Implementation
      resource consumption Implementation
    Implementation
      resource consumption Implementation
    Implementation
      resource consumption Implementation
    Implementation
      resource consumption Implementation
  integer type unint16: base-type=UInt16, range phys 0..32000
  51 x internal behavior:
    InternalBehavior: component=Alarmanlage_Alarmanlage
    InternalBehavior: component=Alarmanlage_Bewegungsmelder
    InternalBehavior: component=Alarmanlage_Hundetaste
    InternalBehavior: component=Alarmanlage_Innenbeleuchtung
    InternalBehavior: component=Alarmanlage_LED
    InternalBehavior: component=Alarmanlage_Sirene
    InternalBehavior: component=Alarmanlage_InnenbeleuchtungLampe
    InternalBehavior: component=Alarmanlage_InnenraumBeleuchtungTaster
    InternalBehavior: component=Tuerkontakte_Tuerverriegleung
    InternalBehavior: component=Tuersystem_Fensterheber_Fensterbewegen
    InternalBehavior: component=Tuersystem_Fensterheber_Fensterpositionsbestimmung
    InternalBehavior: component=Tuersystem_Fensterheber_Impulsgeber
    InternalBehavior: component=Tuersystem_Fensterheber_Initialisierung
    InternalBehavior: component=Tuersystem_Fensterheber_Klemmschutz
    InternalBehavior: component=Tuersystem_Fensterheber_LEDAnzeige
    InternalBehavior: component=Tuersystem_Fensterheber_FensterheberMotor_Actuator
    InternalBehavior: component=Tuersystem_Fensterheber_BCD_A
    InternalBehavior: component=Tuersystem_Fensterheber_BCD_B
    InternalBehavior: component=Tuersystem_Fensterheber_BCD_C
    InternalBehavior: component=Tuersystem_Fensterheber_BCD_D
    InternalBehavior: component=Tuersystem_Fensterheber_Fensterhoch_Taster
    InternalBehavior: component=Tuersystem_Fensterheber_Fensterrunter_Taster
    InternalBehavior: component=Tuersystem_Spiegelstellung_SollHorzAnfahren
    InternalBehavior: component=Tuersystem_Spiegelstellung_SollVertAnfahren
    InternalBehavior: component=Tuersystem_Spiegelstellung_LED_Vertikal_BCD_A
    InternalBehavior: component=Tuersystem_Spiegelstellung_LED_Vertikal_BCD_B
    InternalBehavior: component=Tuersystem_Spiegelstellung_LED_Vertikal_BCD_C
    InternalBehavior: component=Tuersystem_Spiegelstellung_LED_Horizontal_BCD_A
    InternalBehavior: component=Tuersystem_Spiegelstellung_LED_Horizontal_BCD_B
    InternalBehavior: component=Tuersystem_Spiegelstellung_LED_Horizontal_BCD_C
    InternalBehavior: component=Tuersystem_Spiegelstellung_SpiegelMotorHorizontal
    InternalBehavior: component=Tuersystem_Spiegelstellung_SpiegelMotorVertikal
    InternalBehavior: component=Tuersystem_Spiegelstellung_TasterSpiegelHoch
    InternalBehavior: component=Tuersystem_Spiegelstellung_TasterSpiegelRunter
    InternalBehavior: component=Tuersystem_Spiegelstellung_TasterSpiegelLinks
    InternalBehavior: component=Tuersystem_Spiegelstellung_TasterSpiegelRechts
    InternalBehavior: component=Tuersystem_Blinker
    InternalBehavior: component=Tuersystem_Blinkerfunktionalitaet
    InternalBehavior: component=Tuersystem_Spiegelheizung
    InternalBehavior: component=Tuersystem_Tueroeffner
    InternalBehavior: component=Tuersystem_TueroeffnerTaster
    InternalBehavior: component=HMI_HMI
    InternalBehavior: component=SensorAussentemperatur
    InternalBehavior: component=SensorGeschwindigkeit
    InternalBehavior: component=SensorZVTaster
      runnable Runnable: symbol=SensorZVTaster_Runnable
    InternalBehavior: component=SensorTuerkontaktHinten
    InternalBehavior: component=SensorTuerkontaktLinks
    InternalBehavior: component=SensorTuerkontaktRechts
    InternalBehavior: component=SensorSchluessel1
    InternalBehavior: component=SensorSchluessel2
    InternalBehavior: component=TasterBlinker
  sender receiver interface BinSensorActuatorValueInterface
    data value: type=Boolean
  sender receiver interface IntegerValueInterface
    data value: type=unint16
  system SYS_Komfortsystem: communication=communication-matrixs=communication-matrix-instance=communication-matrix-type=CAN_BODY_DBC
    mapping MAPPING
      data-mappings:
        data-element=SWA_Komfortsystem.Human Machine Interface.HMI_HMI.tuerkontakt_hinten.value, signal=Tuerkontakt_hinten
        data-element=SWA_Komfortsystem.Tuersystem.Tuersystem_Spiegelstellung.Tuersystem_Spiegelstellung_SollVertAnfahren.schluessel1_auf.value, signal=Schluessel1_auf
        data-element=SWA_Komfortsystem.Human Machine Interface.HMI_HMI.verriegelt_rechts.value, signal=Tuer_rechts_verriegelt
        data-element=SWA_Komfortsystem.Human Machine Interface.HMI_HMI.tuerkontakt_rechts.value, signal=Tuerkontakt_rechts
        data-element=SWA_Komfortsystem.Human Machine Interface.HMI_HMI.hmi_mitteilung.value, signal=HMI_Mitteilung
        data-element=SWA_Komfortsystem.Human Machine Interface.HMI_HMI.safe_hinten.value, signal=Safe_hinten
        data-element=SWA_Komfortsystem.Alarmanlage.Alarmanlage_Alarmanlage.tuer_hinten_verriegelt.value, signal=Tuer_hinten_verriegelt
        data-element=SWA_Komfortsystem.Alarmanlage.Alarmanlage_Alarmanlage.alarmanlage_OnOff.value, signal=Alarmanlage_OnOff
        data-element=SWA_Komfortsystem.Alarmanlage.Alarmanlage_Alarmanlage.offen_links.value, signal=Tuer_offen_links
        data-element=SWA_Komfortsystem.Alarmanlage.Alarmanlage_Innenbeleuchtung.beleuchtungsdauer.value, signal=HMI_Beleuchtungsdauer
        data-element=SWA_Komfortsystem.SensorSchluessel1.zu.value, signal=Schluessel1_zu
        data-element=SWA_Komfortsystem.SensorTuerkontaktHinten.kontakt.value, signal=Tuerkontakt_hinten
        data-element=SWA_Komfortsystem.TasterBlinker.taster_value.value, signal=Blinker_CAN
        data-element=SWA_Komfortsystem.Tuerkontakte.Tuerkontakte_Tuerverriegleung.blinkenDreiMal.value, signal=BlinkenDreiMal
        data-element=SWA_Komfortsystem.SensorSchluessel1.auf.value, signal=Schluessel1_auf
        data-element=SWA_Komfortsystem.SensorSchluessel1.auf.value, signal=Schluessel1_auf
        data-element=SWA_Komfortsystem.SensorSchluessel1.auf.value, signal=Schluessel1_auf
        data-element=SWA_Komfortsystem.Tuerkontakte.Tuerkontakte_Tuerverriegleung.safe_rechts.value, signal=Safe_rechts
        data-element=SWA_Komfortsystem.SensorTuerkontaktRechts.offen.value, signal=Tuer_offen_rechts
        data-element=SWA_Komfortsystem.SensorTuerkontaktRechts.offen.value, signal=Tuer_offen_rechts
        data-element=SWA_Komfortsystem.Alarmanlage.Alarmanlage_Alarmanlage.objekt_erkannt.value, signal=Objekt_erkannt
        data-element=SWA_Komfortsystem.SensorGeschwindigkeit.geschwindigkeit.value, signal=Geschwindigkeit
        data-element=SWA_Komfortsystem.Human Machine Interface.HMI_HMI.hmi_quittierung.value, signal=HMI_Quittierung
        data-element=SWA_Komfortsystem.Tuerkontakte.Tuerkontakte_Tuerverriegleung.tuer_hinten_verriegelt.value, signal=Tuer_hinten_verriegelt
        data-element=SWA_Komfortsystem.Tuerkontakte.Tuerkontakte_Tuerverriegleung.tuer_hinten_verriegelt.value, signal=Tuer_hinten_verriegelt
        data-element=SWA_Komfortsystem.Human Machine Interface.HMI_HMI.verriegelt_hinten.value, signal=Tuer_hinten_verriegelt
        data-element=SWA_Komfortsystem.Alarmanlage.Alarmanlage_Alarmanlage.hmi_quittierung.value, signal=HMI_Quittierung
        data-element=SWA_Komfortsystem.Alarmanlage.Alarmanlage_Alarmanlage.offen_rechts.value, signal=Tuer_offen_rechts
        data-element=SWA_Komfortsystem.Human Machine Interface.HMI_HMI.safe_rechts.value, signal=Safe_rechts
        data-element=SWA_Komfortsystem.Alarmanlage.Alarmanlage_Alarmanlage.offen_hinten.value, signal=Tuer_offen_hinten
        data-element=SWA_Komfortsystem.SensorTuerkontaktLinks.kontakt.value, signal=Tuerkontakt_links
        data-element=SWA_Komfortsystem.Alarmanlage.Alarmanlage_Alarmanlage.schluessel2_auf.value, signal=Schluessel2_auf
        data-element=SWA_Komfortsystem.Alarmanlage.Alarmanlage_Alarmanlage.schluessel1_auf.value, signal=Schluessel1_auf
        data-element=SWA_Komfortsystem.Tuerkontakte.Tuerkontakte_Tuerverriegleung.safe_links.value, signal=Safe_links
        data-element=SWA_Komfortsystem.Tuersystem.Tuersystem_Spiegelstellung.Tuersystem_Spiegelstellung_SollHorzAnfahren.schluessel1_auf.value, signal=Schluessel1_auf
        data-element=SWA_Komfortsystem.Tuersystem.Tuersystem_Spiegelstellung.Tuersystem_Spiegelstellung_SollVertAnfahren.schluessel2_auf.value, signal=Schluessel2_auf
        data-element=SWA_Komfortsystem.SensorSchluessel2.auf.value, signal=Schluessel2_auf
        data-element=SWA_Komfortsystem.SensorSchluessel2.auf.value, signal=Schluessel2_auf
        data-element=SWA_Komfortsystem.SensorSchluessel2.auf.value, signal=Schluessel2_auf
        data-element=SWA_Komfortsystem.Alarmanlage.Alarmanlage_Innenbeleuchtung.offen_links.value, signal=Tuer_offen_links
        data-element=SWA_Komfortsystem.Tuerkontakte.Tuerkontakte_Tuerverriegleung.zv_aus.value, signal=Zentralverriegelung_Aus
        data-element=SWA_Komfortsystem.Alarmanlage.Alarmanlage_Innenbeleuchtung.schluessel2_zu.value, signal=Schluessel2_zu
        data-element=SWA_Komfortsystem.Human Machine Interface.HMI_HMI.objekt_erkannt.value, signal=Objekt_erkannt
        data-element=SWA_Komfortsystem.Tuersystem.Tuersystem_Spiegelheizung.newValue.value, signal=Aussentemperatur
        data-element=SWA_Komfortsystem.Tuerkontakte.Tuerkontakte_Tuerverriegleung.tuer_links_verriegelt.value, signal=Tuer_links_verriegelt
        data-element=SWA_Komfortsystem.Tuerkontakte.Tuerkontakte_Tuerverriegleung.tuer_links_verriegelt.value, signal=Tuer_links_verriegelt
        data-element=SWA_Komfortsystem.SensorZVTaster.zv_ein.value, signal=Zentralverriegelung_Ein
        data-element=SWA_Komfortsystem.SensorZVTaster.zv_ein.value, signal=Zentralverriegelung_Ein
        data-element=SWA_Komfortsystem.Human Machine Interface.HMI_HMI.IRUE_status.value, signal=IRUE_Status
        data-element=SWA_Komfortsystem.Alarmanlage.Alarmanlage_Innenbeleuchtung.offen_rechts.value, signal=Tuer_offen_rechts
        data-element=SWA_Komfortsystem.Alarmanlage.Alarmanlage_Alarmanlage.tuer_rechts_verriegelt.value, signal=Tuer_rechts_verriegelt
        data-element=SWA_Komfortsystem.Alarmanlage.Alarmanlage_Innenbeleuchtung.offen_hinten.value, signal=Tuer_offen_hinten
        data-element=SWA_Komfortsystem.Alarmanlage.Alarmanlage_Alarmanlage.hmi_alarm_an.value, signal=HMI_Alarm_An
        data-element=SWA_Komfortsystem.SensorTuerkontaktHinten.offen.value, signal=Tuer_offen_hinten
        data-element=SWA_Komfortsystem.SensorTuerkontaktHinten.offen.value, signal=Tuer_offen_hinten
        data-element=SWA_Komfortsystem.Alarmanlage.Alarmanlage_Alarmanlage.IRUE_status.value, signal=IRUE_Status
        data-element=SWA_Komfortsystem.Tuerkontakte.Tuerkontakte_Tuerverriegleung.safe_hinten.value, signal=Safe_hinten
        data-element=SWA_Komfortsystem.SensorTuerkontaktRechts.kontakt.value, signal=Tuerkontakt_rechts
        data-element=SWA_Komfortsystem.Tuersystem.Tuersystem_Spiegelstellung.Tuersystem_Spiegelstellung_SollHorzAnfahren.schluessel2_auf.value, signal=Schluessel2_auf
        data-element=SWA_Komfortsystem.Alarmanlage.Alarmanlage_Innenbeleuchtung.schluessel1_zu.value, signal=Schluessel1_zu
        data-element=SWA_Komfortsystem.Human Machine Interface.HMI_HMI.verriegelt_links.value, signal=Tuer_links_verriegelt
        data-element=SWA_Komfortsystem.Tuerkontakte.Tuerkontakte_Tuerverriegleung.tuer_rechts_verriegelt.value, signal=Tuer_rechts_verriegelt
        data-element=SWA_Komfortsystem.Tuerkontakte.Tuerkontakte_Tuerverriegleung.tuer_rechts_verriegelt.value, signal=Tuer_rechts_verriegelt
        data-element=SWA_Komfortsystem.Tuersystem.Tuersystem_Blinkerfunktionalitaet.Blinker_CAN.value, signal=Blinker_CAN
        data-element=SWA_Komfortsystem.Tuerkontakte.Tuerkontakte_Tuerverriegleung.zv_ein.value, signal=Zentralverriegelung_Ein
        data-element=SWA_Komfortsystem.SensorZVTaster.zv_aus.value, signal=Zentralverriegelung_Aus
        data-element=SWA_Komfortsystem.Human Machine Interface.HMI_HMI.alarmOnOff.value, signal=Alarmanlage_OnOff
        data-element=SWA_Komfortsystem.Alarmanlage.Alarmanlage_Alarmanlage.ALARM.value, signal=Alarm
        data-element=SWA_Komfortsystem.SensorSchluessel2.zu.value, signal=Schluessel2_zu
        data-element=SWA_Komfortsystem.Human Machine Interface.HMI_HMI.tuerkontakt_links.value, signal=Tuerkontakt_links
        data-element=SWA_Komfortsystem.Human Machine Interface.HMI_HMI.beleuchtungsdauer.value, signal=HMI_Beleuchtungsdauer
        data-element=SWA_Komfortsystem.Human Machine Interface.HMI_HMI.safe_links.value, signal=Safe_links
        data-element=SWA_Komfortsystem.Tuersystem.Tuersystem_Blinkerfunktionalitaet.ALARM.value, signal=Alarm
        data-element=SWA_Komfortsystem.SensorTuerkontaktLinks.offen.value, signal=Tuer_offen_links
        data-element=SWA_Komfortsystem.SensorTuerkontaktLinks.offen.value, signal=Tuer_offen_links
        data-element=SWA_Komfortsystem.SensorAussentemperatur.unterEinGrad.value, signal=Aussentemperatur
        data-element=SWA_Komfortsystem.Tuersystem.Tuersystem_Fensterheber.Tuersystem_Fensterheber_Fensterbewegen.zv_ein.value, signal=Zentralverriegelung_Ein
        data-element=SWA_Komfortsystem.Alarmanlage.Alarmanlage_Alarmanlage.tuer_links_verriegelt.value, signal=Tuer_links_verriegelt
        data-element=SWA_Komfortsystem.Human Machine Interface.HMI_HMI.hmi_alarm_an.value, signal=HMI_Alarm_An
        data-element=SWA_Komfortsystem.Tuersystem.Tuersystem_Blinkerfunktionalitaet.BlinkenDreiMal.value, signal=BlinkenDreiMal
        data-element=SWA_Komfortsystem.Alarmanlage.Alarmanlage_Alarmanlage.HMI_Mitteilung.value, signal=HMI_Mitteilung
        data-element=SWA_Komfortsystem.Tuerkontakte.Tuerkontakte_Tuerverriegleung.geschw_meldung.value, signal=Geschwindigkeit
      sw-impl-mappings:
        51 x sw comp to impl mapping, all with component-implementation=Komfortsystem/Implementation:
          ImplementationMapping1: component=SWA_Komfortsystem.Tuersystem.Tuersystem_Spiegelstellung.Tuersystem_Spiegelstellung_LED_Horizontal_BCD_A
          ImplementationMapping2: component=SWA_Komfortsystem.Tuersystem.Tuersystem_Blinker
          ImplementationMapping3: component=SWA_Komfortsystem.Tuersystem.Tuersystem_Fensterheber.Tuersystem_Fensterheber_BCD_A
          ImplementationMapping4: component=SWA_Komfortsystem.Human Machine Interface.HMI_HMI
          ImplementationMapping5: component=SWA_Komfortsystem.TasterBlinker
          ImplementationMapping6: component=SWA_Komfortsystem.Alarmanlage.Alarmanlage_Innenbeleuchtung
          ImplementationMapping7: component=SWA_Komfortsystem.Alarmanlage.Alarmanlage_InnenbeleuchtungLampe
          ImplementationMapping8: component=SWA_Komfortsystem.Tuersystem.Tuersystem_Spiegelstellung.Tuersystem_Spiegelstellung_LED_Horizontal_BCD_B
          ImplementationMapping9: component=SWA_Komfortsystem.Tuersystem.Tuersystem_Spiegelstellung.Tuersystem_Spiegelstellung_SpiegelMotorHorizontal
          ImplementationMapping10: component=SWA_Komfortsystem.SensorAussentemperatur
          ImplementationMapping11: component=SWA_Komfortsystem.SensorGeschwindigkeit
          ImplementationMapping12: component=SWA_Komfortsystem.Tuersystem.Tuersystem_Fensterheber.Tuersystem_Fensterheber_BCD_C
          ImplementationMapping13: component=SWA_Komfortsystem.Alarmanlage.Alarmanlage_InnenraumBeleuchtungTaster
          ImplementationMapping14: component=SWA_Komfortsystem.Tuersystem.Tuersystem_Fensterheber.Tuersystem_Fensterheber_BCD_B
          ImplementationMapping15: component=SWA_Komfortsystem.SensorTuerkontaktRechts
          ImplementationMapping16: component=SWA_Komfortsystem.Tuersystem.Tuersystem_Fensterheber.Tuersystem_Fensterheber_BCD_D
          ImplementationMapping17: component=SWA_Komfortsystem.Tuersystem.Tuersystem_Tueroeffner
          ImplementationMapping18: component=SWA_Komfortsystem.SensorSchluessel1
          ImplementationMapping19: component=SWA_Komfortsystem.Tuersystem.Tuersystem_Fensterheber.Tuersystem_Fensterheber_Fensterpositionsbestimmung
          ImplementationMapping20: component=SWA_Komfortsystem.SensorZVTaster
          ImplementationMapping21: component=SWA_Komfortsystem.Tuersystem.Tuersystem_Spiegelstellung.Tuersystem_Spiegelstellung_LED_Vertikal_BCD_C
          ImplementationMapping22: component=SWA_Komfortsystem.Tuersystem.Tuersystem_Fensterheber.Tuersystem_Fensterheber_Fensterbewegen
          ImplementationMapping23: component=SWA_Komfortsystem.Alarmanlage.Alarmanlage_Bewegungsmelder
          ImplementationMapping24: component=SWA_Komfortsystem.Tuersystem.Tuersystem_Fensterheber.Tuersystem_Fensterheber_FensterheberMotor_Actuator
          ImplementationMapping25: component=SWA_Komfortsystem.Tuersystem.Tuersystem_Spiegelstellung.Tuersystem_Spiegelstellung_TasterSpiegelRunter
          ImplementationMapping26: component=SWA_Komfortsystem.SensorSchluessel2
          ImplementationMapping27: component=SWA_Komfortsystem.Tuersystem.Tuersystem_Fensterheber.Tuersystem_Fensterheber_Initialisierung
          ImplementationMapping28: component=SWA_Komfortsystem.Tuerkontakte.Tuerkontakte_Tuerverriegleung
          ImplementationMapping29: component=SWA_Komfortsystem.Tuersystem.Tuersystem_Spiegelstellung.Tuersystem_Spiegelstellung_SollHorzAnfahren
          ImplementationMapping30: component=SWA_Komfortsystem.SensorTuerkontaktHinten
          ImplementationMapping31: component=SWA_Komfortsystem.Tuersystem.Tuersystem_Spiegelstellung.Tuersystem_Spiegelstellung_LED_Vertikal_BCD_A
          ImplementationMapping32: component=SWA_Komfortsystem.Tuersystem.Tuersystem_Fensterheber.Tuersystem_Fensterheber_Fensterrunter_Taster
          ImplementationMapping33: component=SWA_Komfortsystem.Tuersystem.Tuersystem_Fensterheber.Tuersystem_Fensterheber_Impulsgeber
          ImplementationMapping34: component=SWA_Komfortsystem.Tuersystem.Tuersystem_Fensterheber.Tuersystem_Fensterheber_LEDAnzeige
          ImplementationMapping35: component=SWA_Komfortsystem.SensorTuerkontaktLinks
          ImplementationMapping36: component=SWA_Komfortsystem.Tuersystem.Tuersystem_TueroeffnerTaster
          ImplementationMapping37: component=SWA_Komfortsystem.Tuersystem.Tuersystem_Spiegelstellung.Tuersystem_Spiegelstellung_TasterSpiegelHoch
          ImplementationMapping38: component=SWA_Komfortsystem.Alarmanlage.Alarmanlage_Alarmanlage
          ImplementationMapping39: component=SWA_Komfortsystem.Tuersystem.Tuersystem_Spiegelstellung.Tuersystem_Spiegelstellung_SollVertAnfahren
          ImplementationMapping40: component=SWA_Komfortsystem.Tuersystem.Tuersystem_Spiegelstellung.Tuersystem_Spiegelstellung_SpiegelMotorVertikal
          ImplementationMapping41: component=SWA_Komfortsystem.Tuersystem.Tuersystem_Spiegelstellung.Tuersystem_Spiegelstellung_LED_Vertikal_BCD_B
          ImplementationMapping42: component=SWA_Komfortsystem.Alarmanlage.Alarmanlage_Hundetaste
          ImplementationMapping43: component=SWA_Komfortsystem.Tuersystem.Tuersystem_Blinkerfunktionalitaet
          ImplementationMapping44: component=SWA_Komfortsystem.Tuersystem.Tuersystem_Fensterheber.Tuersystem_Fensterheber_Klemmschutz
          ImplementationMapping45: component=SWA_Komfortsystem.Alarmanlage.Alarmanlage_LED
          ImplementationMapping46: component=SWA_Komfortsystem.Tuersystem.Tuersystem_Spiegelstellung.Tuersystem_Spiegelstellung_TasterSpiegelRechts
          ImplementationMapping47: component=SWA_Komfortsystem.Alarmanlage.Alarmanlage_Sirene
          ImplementationMapping48: component=SWA_Komfortsystem.Tuersystem.Tuersystem_Spiegelstellung.Tuersystem_Spiegelstellung_LED_Horizontal_BCD_C
          ImplementationMapping49: component=SWA_Komfortsystem.Tuersystem.Tuersystem_Fensterheber.Tuersystem_Fensterheber_Fensterhoch_Taster
          ImplementationMapping50: component=SWA_Komfortsystem.Tuersystem.Tuersystem_Spiegelheizung
          ImplementationMapping51: component=SWA_Komfortsystem.Tuersystem.Tuersystem_Spiegelstellung.Tuersystem_Spiegelstellung_TasterSpiegelLinks
      sw-mappings:
        5 x sw comp to ecu mapping:
          a028421d714c346f79a3707a4408401: component=SWA_Komfortsystem.Tuersystem, ecu-instance=HWT_Komfortsystem.DoorEcu
          ad7e572505d5b4fddb40e8fa4f74760: ecu-instance=HWT_Komfortsystem.RestbusSimEcu
            component:
              SWA_Komfortsystem.SensorAussentemperatur
              SWA_Komfortsystem.SensorGeschwindigkeit
              SWA_Komfortsystem.TasterBlinker
          a4807b992070046028b019db5846cd7: component=[SWA_Komfortsystem.SensorZVTaster, SWA_Komfortsystem.Alarmanlage], ecu-instance=HWT_Komfortsystem.AlarmEcu
          acd12fdf3a1bf4110a360e645d68be8: ecu-instance=HWT_Komfortsystem.LockEcu
            component:
              SWA_Komfortsystem.Tuerkontakte
              SWA_Komfortsystem.SensorSchluessel1
              SWA_Komfortsystem.SensorSchluessel2
              SWA_Komfortsystem.SensorTuerkontaktHinten
              SWA_Komfortsystem.SensorTuerkontaktLinks
              SWA_Komfortsystem.SensorTuerkontaktRechts
          afc40f264d05a4d058512f136494f39: component=SWA_Komfortsystem.Human Machine Interface, ecu-instance=HWT_Komfortsystem.HmiEcu
    software composition SWA_Komfortsystem: software-composition=SWA_Komfortsystem
    topology HWT_Komfortsystem: topology=HWT_Komfortsystem
  system topology type HWT_Komfortsystem
    communication-clusters:
      can bus CAN_BODY: communication-speed-bus=100000  # CAN bus zur Kommunikation zwischen den Steuergeräten (Body-ECUs)
        physical channel CAN_BODY: physical-medium-segment{connected-ecu=[DoorEcu, LockEcu, AlarmEcu, HmiEcu, RestbusSimEcu], physical-medium-data-lines=1}
    topology-elements:
      5 x ecu instance:
        DoorEcu  # @price 1 @location left @sensorsLeft 6 @actuatorsLeft 4
          comm-ports:
            can communication port instance DOOR_COMPORT: comm-port-id=0, communication-speed-port=100000, wake-up-on-comm-port-supported=false
        LockEcu  # @price 1 @location left @sensorsFront 2 @actuatorsFront 1 @sensorsLeft 1 @actuatorsLeft 1
          comm-ports:
            can communication port instance LOCK_COMPORT: comm-port-id=0, communication-speed-port=100000, wake-up-on-comm-port-supported=false
        AlarmEcu  # @price 1 @location rear @sensorsFront 1 @actuatorsRear 1
          comm-ports:
            can communication port instance ALARM_COMPORT: comm-port-id=0, communication-speed-port=100000, wake-up-on-comm-port-supported=false
        HmiEcu  # @price 1 @location front @sensorsFront 3 @actuatorsFront 1
          comm-ports:
            can communication port instance HMI_COMPORT: comm-port-id=0, communication-speed-port=100000, wake-up-on-comm-port-supported=false
        RestbusSimEcu
          comm-ports:
            can communication port instance RBS_COMPORT: comm-port-id=0, communication-speed-port=100000, wake-up-on-comm-port-supported=false
package /Komfortsystem/NWC_Komfortsystem/CAN_BODY_DBC
  30 x system signal:
    Alarm: signal-length=1
    Alarmanlage_OnOff: signal-length=1
    Aussentemperatur: signal-length=1
    BlinkenDreiMal: signal-length=1
    Blinker_CAN: signal-length=1
    Geschwindigkeit: signal-length=16
    HMI_Alarm_An: signal-length=1
    HMI_Beleuchtungsdauer: signal-length=16
    HMI_Mitteilung: signal-length=1
    HMI_Quittierung: signal-length=1
    IRUE_Status: signal-length=1
    Objekt_erkannt: signal-length=1
    Safe_hinten: signal-length=1
    Safe_links: signal-length=1
    Safe_rechts: signal-length=1
    Schluessel1_auf: signal-length=1
    Schluessel1_zu: signal-length=1
    Schluessel2_auf: signal-length=1
    Schluessel2_zu: signal-length=1
    Tuer_hinten_verriegelt: signal-length=1
    Tuer_links_verriegelt: signal-length=1
    Tuer_offen_hinten: signal-length=1
    Tuer_offen_links: signal-length=1
    Tuer_offen_rechts: signal-length=1
    Tuer_rechts_verriegelt: signal-length=1
    Tuerkontakt_hinten: signal-length=1
    Tuerkontakt_links: signal-length=1
    Tuerkontakt_rechts: signal-length=1
    Zentralverriegelung_Aus: signal-length=1
    Zentralverriegelung_Ein: signal-length=1
